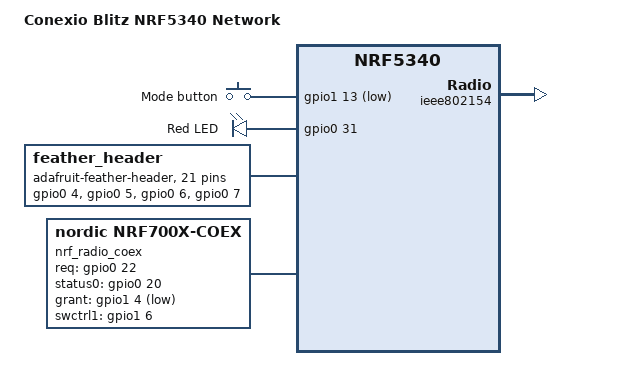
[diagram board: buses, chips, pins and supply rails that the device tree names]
/*
 * Copyright (c) 2024 Conexio Technologies, Inc
 * Copyright (c) 2022 Nordic Semiconductor
 *
 * SPDX-License-Identifier: Apache-2.0
 */

/dts-v1/;
#include <nordic/nrf5340_cpunet_qkaa.dtsi>
#include "conexio_blitz_cpunet-pinctrl.dtsi"
#include <zephyr/dt-bindings/input/input-event-codes.h>

/ {
	model = "Conexio Blitz NRF5340 Network";
	compatible = "conexio,conexio-blitz-cpunet";

	chosen {
		zephyr,console = &uart0;
		zephyr,shell-uart = &uart0;
		zephyr,uart-mcumgr = &uart0;
		zephyr,bt-mon-uart = &uart0;
		zephyr,bt-c2h-uart = &uart0;
		zephyr,bt-hci-ipc = &ipc0;
		nordic,802154-spinel-ipc = &ipc0;
		zephyr,sram = &sram1;
		zephyr,flash = &flash1;
		zephyr,code-partition = &slot0_partition;
		zephyr,ieee802154 = &ieee802154;
	};

	buttons {
		compatible = "gpio-keys";
		button0: button_0 {
			gpios = <&gpio1 13 (GPIO_PULL_UP | GPIO_ACTIVE_LOW)>;
			label = "Mode button";
			zephyr,code = <INPUT_KEY_0>;
		};
	};

	leds {
		compatible = "gpio-leds";
		red_led: led_0 {
			gpios = <&gpio0 31 GPIO_ACTIVE_HIGH>;
			label = "Red LED";
		};
	};

	feather_header: feather_connector {
		compatible = "adafruit-feather-header";
		#gpio-cells = <2>;
		gpio-map-mask = <0xffffffff 0xffffffc0>;
		gpio-map-pass-thru = <0 0x3f>;
		gpio-map = <0 0 &gpio0 4 0>,	/* A0 */
			   <1 0 &gpio0 5 0>,	/* A1 */
			   <2 0 &gpio0 6 0>,	/* A2 */
			   <3 0 &gpio0 7 0>,	/* A3 */
			   <4 0 &gpio0 25 0>,	/* A4 */
			   <5 0 &gpio0 26 0>,	/* A5 */
			   <6 0 &gpio0 29 0>,	/* SCK */
			   <7 0 &gpio0 28 0>,	/* MOSI */
			   <8 0 &gpio0 30 0>,	/* MISO */
			   <9 0 &gpio1 11 0>,	/* RXD */
			   <10 0 &gpio1 12 0>,	/* TXD */
			   <11 0 &gpio1 0 0>,	/* D2 */
			   <12 0 &gpio1 2 0>,	/* SDA */
			   <13 0 &gpio1 3 0>,	/* SCL */
			   <14 0 &gpio1 1 0>,	/* D5 */
			   <15 0 &gpio0 8 0>,	/* D6 */
			   <16 0 &gpio0 9 0>,	/* D9 */
			   <17 0 &gpio0 10 0>,	/* D10 */
			   <18 0 &gpio0 11 0>,	/* D11 */
			   <19 0 &gpio0 12 0>,	/* D12 */
			   <20 0 &gpio0 24 0>;	/* D13 */
	};

	nrf_radio_coex: nrf7002-coex {
		status = "okay";
		compatible = "nordic,nrf700x-coex";
		req-gpios = <&gpio0 22 GPIO_ACTIVE_HIGH>;
		status0-gpios = <&gpio0 20 GPIO_ACTIVE_HIGH>;
		grant-gpios = <&gpio1 4 (GPIO_PULL_DOWN | GPIO_ACTIVE_LOW)>;
		swctrl1-gpios = <&gpio1 6 GPIO_ACTIVE_HIGH>;
	};

	aliases {
		sw0 = &button0;
		led0 = &red_led;
		watchdog0 = &wdt;
	};
};

&gpiote {
	status = "okay";
};

&gpio0 {
	status = "okay";
};

&gpio1 {
	status = "okay";
};

&uart0 {
	compatible = "nordic,nrf-uarte";
	status = "disabled";
	current-speed = <115200>;
	pinctrl-0 = <&uart0_default>;
	pinctrl-1 = <&uart0_sleep>;
	pinctrl-names = "default", "sleep";
};

&flash1 {

	partitions {
		compatible = "fixed-partitions";
		#address-cells = <1>;
		#size-cells = <1>;

		boot_partition: partition@0 {
			label = "mcuboot";
			reg = <0x00000000 0xc000>;
		};
		slot0_partition: partition@c000 {
			label = "image-0";
			reg = <0x0000C000 0x17000>;
		};
		slot1_partition: partition@23000 {
			label = "image-1";
			reg = <0x00023000 0x17000>;
		};
		storage_partition: partition@3a000 {
			label = "storage";
			reg = <0x0003a000 0x6000>;
		};
	};
};

&ieee802154 {
	status = "okay";
};

/* Include shared RAM configuration file */
#include "conexio_blitz_shared_sram_planning_conf.dtsi"
